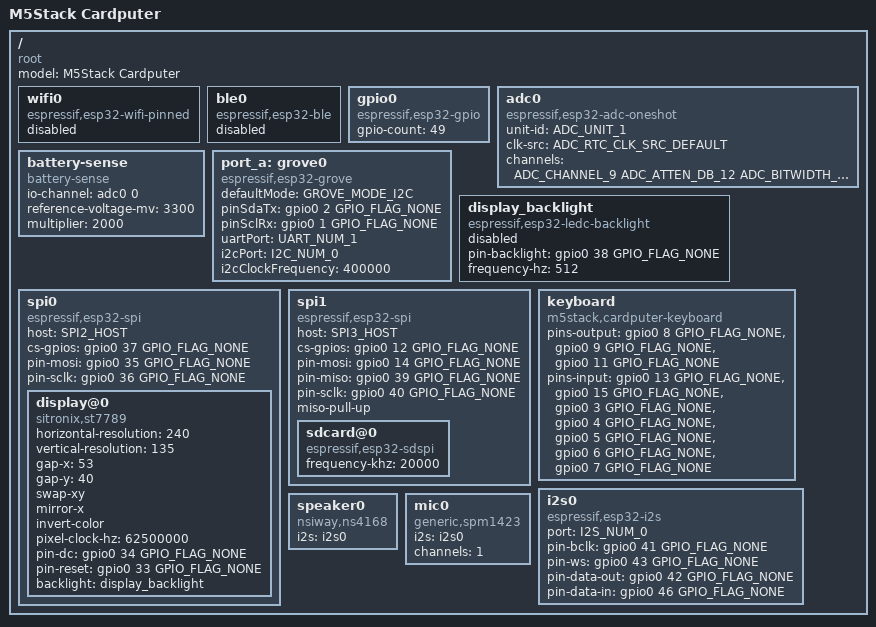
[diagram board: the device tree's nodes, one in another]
/dts-v1/;

#include <tactility/bindings/root.h>
#include <tactility/bindings/battery_sense.h>
#include <tactility/bindings/esp32_adc_oneshot.h>
#include <tactility/bindings/esp32_ble.h>
#include <tactility/bindings/esp32_wifi_pinned.h>
#include <tactility/bindings/esp32_gpio.h>
#include <tactility/bindings/esp32_grove.h>
#include <tactility/bindings/esp32_i2c.h>
#include <tactility/bindings/esp32_i2s.h>
#include <tactility/bindings/esp32_spi.h>
#include <tactility/bindings/esp32_uart.h>
#include <tactility/bindings/esp32_sdspi.h>
#include <tactility/bindings/esp32_ledc_backlight.h>

#include <bindings/st7789.h>
#include <bindings/cardputer_keyboard.h>
#include <bindings/dummy_i2s_amp.h>
#include <bindings/pdm_mic.h>

// Reference: https://docs.m5stack.com/en/core/Cardputer
/ {
	compatible = "root";
	model = "M5Stack Cardputer";

	wifi0 {
		compatible = "espressif,esp32-wifi-pinned";
		status = "disabled";
	};

	ble0 {
		compatible = "espressif,esp32-ble";
		status = "disabled";
	};

	gpio0 {
		compatible = "espressif,esp32-gpio";
		gpio-count = <49>;
	};

	adc0 {
		compatible = "espressif,esp32-adc-oneshot";
		unit-id = <ADC_UNIT_1>;
		clk-src = <ADC_RTC_CLK_SRC_DEFAULT>;
		// GPIO10 (ADC1_CHANNEL_9 on ESP32-S3): battery voltage sense, behind a 1:2 divider.
		channels = <ADC_CHANNEL_9 ADC_ATTEN_DB_12 ADC_BITWIDTH_DEFAULT>;
	};

	battery-sense {
		compatible = "battery-sense";
		io-channel = <&adc0 0>;
		reference-voltage-mv = <3300>;
		multiplier = <2000>;
	};

	port_a: grove0 {
		compatible = "espressif,esp32-grove";
		defaultMode = <GROVE_MODE_I2C>;
		pinSdaTx = <&gpio0 2 GPIO_FLAG_NONE>;
		pinSclRx = <&gpio0 1 GPIO_FLAG_NONE>;
		uartPort = <UART_NUM_1>;
		i2cPort = <I2C_NUM_0>;
		i2cClockFrequency = <400000>;
	};

	display_backlight {
		compatible = "espressif,esp32-ledc-backlight";
		// Off by default so display power-on won't show the screen from before the last power loss.
		// The display backlight is turned on during the boot process.
		status = "disabled";
		pin-backlight = <&gpio0 38 GPIO_FLAG_NONE>;
		frequency-hz = <512>;
	};

	spi0 {
		compatible = "espressif,esp32-spi";
		host = <SPI2_HOST>;
		cs-gpios = <&gpio0 37 GPIO_FLAG_NONE>;
		pin-mosi = <&gpio0 35 GPIO_FLAG_NONE>;
		pin-sclk = <&gpio0 36 GPIO_FLAG_NONE>;

		display@0 {
			compatible = "sitronix,st7789";
			horizontal-resolution = <240>;
			vertical-resolution = <135>;
			// Should be 52 according to https://github.com/m5stack/M5GFX/blob/master/src/M5GFX.cpp but this leaves a gap at the bottom
			gap-x = <53>;
			gap-y = <40>;
			swap-xy;
			mirror-x;
			invert-color;
			pixel-clock-hz = <62500000>;
			pin-dc = <&gpio0 34 GPIO_FLAG_NONE>;
			pin-reset = <&gpio0 33 GPIO_FLAG_NONE>;
			backlight = <&display_backlight>;
		};
	};

	spi1 {
		compatible = "espressif,esp32-spi";
		host = <SPI3_HOST>;
		cs-gpios = <&gpio0 12 GPIO_FLAG_NONE>;
		pin-mosi = <&gpio0 14 GPIO_FLAG_NONE>;
		pin-miso = <&gpio0 39 GPIO_FLAG_NONE>;
		pin-sclk = <&gpio0 40 GPIO_FLAG_NONE>;
		miso-pull-up;

		sdcard@0 {
			compatible = "espressif,esp32-sdspi";
			frequency-khz = <20000>;
		};
	};

	keyboard {
		compatible = "m5stack,cardputer-keyboard";
		pins-output = <&gpio0 8 GPIO_FLAG_NONE>,
		              <&gpio0 9 GPIO_FLAG_NONE>,
		              <&gpio0 11 GPIO_FLAG_NONE>;
		pins-input = <&gpio0 13 GPIO_FLAG_NONE>,
		             <&gpio0 15 GPIO_FLAG_NONE>,
		             <&gpio0 3 GPIO_FLAG_NONE>,
		             <&gpio0 4 GPIO_FLAG_NONE>,
		             <&gpio0 5 GPIO_FLAG_NONE>,
		             <&gpio0 6 GPIO_FLAG_NONE>,
		             <&gpio0 7 GPIO_FLAG_NONE>;
	};

	// Speaker (std TX) and PDM mic (RX) share this single I2S controller. PDM RX is
	// hardware-restricted to I2S controller 0 on ESP32 targets, and per schematic the
	// mic's PDM CLK and the speaker's LRCLK both land on GPIO43 anyway -- splitting them
	// across two controllers (as M5Stack's own reference firmware does) isn't possible
	// here since Tactility's GPIO ownership model is exclusive-acquire-only (no pin
	// sharing), and two I2S controllers both declaring GPIO43 would have one fail to
	// start. Keeping both on one controller means only one acquire of GPIO43 happens;
	// audio_codec_data_if_i2s.c's data_set_fmt() already tears down and recreates the
	// channel on each codec open(), so opening one direction after the other naturally
	// reconfigures the shared port/pin -- speaker and mic still cannot be used
	// simultaneously, which matches the hardware reality.
	i2s0 {
		compatible = "espressif,esp32-i2s";
		port = <I2S_NUM_0>;
		pin-bclk = <&gpio0 41 GPIO_FLAG_NONE>;
		pin-ws = <&gpio0 43 GPIO_FLAG_NONE>;
		pin-data-out = <&gpio0 42 GPIO_FLAG_NONE>;
		pin-data-in = <&gpio0 46 GPIO_FLAG_NONE>;
	};

	speaker0 {
		compatible = "nsiway,ns4168";
		i2s = <&i2s0>;
	};

	mic0 {
		compatible = "generic,spm1423";
		i2s = <&i2s0>;
		channels = <1>;
	};
};
